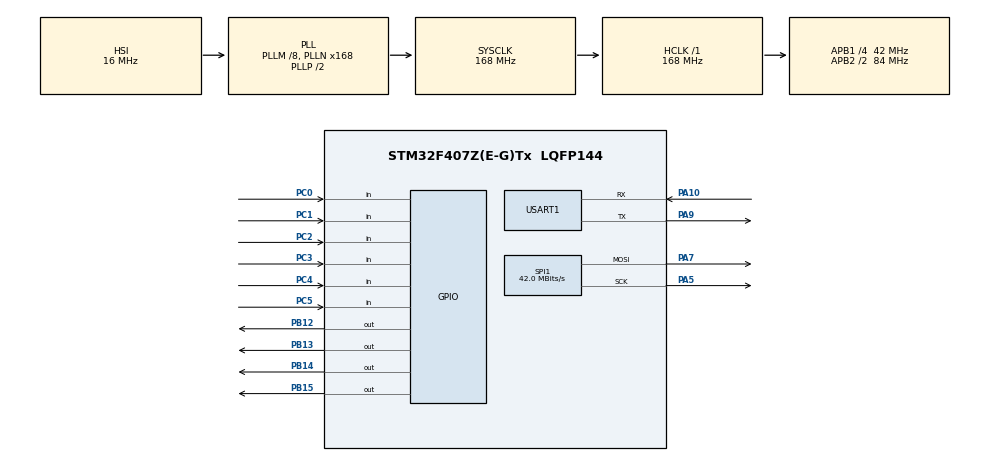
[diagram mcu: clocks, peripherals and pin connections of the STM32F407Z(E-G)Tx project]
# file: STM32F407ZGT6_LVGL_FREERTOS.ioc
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FREERTOS.Tasks01=defaultTask,24,128,StartDefaultTask,Default,NULL,Dynamic,NULL,NULL
Mcu.Family=STM32F4
Mcu.Name=STM32F407Z(E-G)Tx
Mcu.Package=LQFP144
NVIC.PriorityGroup=NVIC_PRIORITYGROUP_4
NVIC.TIM6_DAC_IRQn=true\:15\:0\:false\:false\:true\:false\:false\:true\:true
NVIC.TimeBase=TIM6_DAC_IRQn
NVIC.TimeBaseIP=TIM6
NVIC.USART1_IRQn=true\:5\:0\:false\:false\:true\:true\:true\:true\:true
PA10.Mode=Asynchronous
PA10.Signal=USART1_RX
PA5.Mode=TX_Only_Simplex_Unidirect_Master
PA5.Signal=SPI1_SCK
PA7.Mode=TX_Only_Simplex_Unidirect_Master
PA7.Signal=SPI1_MOSI
PA9.Mode=Asynchronous
PA9.Signal=USART1_TX
PB12.Signal=GPIO_Output
PB13.Signal=GPIO_Output
PB14.Signal=GPIO_Output
PB15.Signal=GPIO_Output
PC0.GPIO_PuPd=GPIO_PULLUP
PC0.Signal=GPIO_Input
PC1.GPIO_PuPd=GPIO_PULLUP
PC1.Signal=GPIO_Input
PC2.GPIO_PuPd=GPIO_PULLUP
PC2.Signal=GPIO_Input
PC3.GPIO_PuPd=GPIO_PULLUP
PC3.Signal=GPIO_Input
PC4.GPIO_PuPd=GPIO_PULLUP
PC4.Signal=GPIO_Input
PC5.GPIO_PuPd=GPIO_PULLUP
PC5.Signal=GPIO_Input
ProjectManager.HeapSize=0x200
ProjectManager.StackSize=0x400
ProjectManager.TargetToolchain=MDK-ARM V5.32
RCC.48MHZClocksFreq_Value=84000000
RCC.AHBFreq_Value=168000000
RCC.APB1CLKDivider=RCC_HCLK_DIV4
RCC.APB1Freq_Value=42000000
RCC.APB1TimFreq_Value=84000000
RCC.APB2CLKDivider=RCC_HCLK_DIV2
RCC.APB2Freq_Value=84000000
RCC.APB2TimFreq_Value=168000000
RCC.CortexFreq_Value=168000000
RCC.HCLKFreq_Value=168000000
RCC.HSE_VALUE=25000000
RCC.HSI_VALUE=16000000
RCC.LSE_VALUE=32768
RCC.PLLM=8
RCC.PLLN=168
RCC.SYSCLKFreq_VALUE=168000000
RCC.SYSCLKSource=RCC_SYSCLKSOURCE_PLLCLK
RCC.VCOOutputFreq_Value=336000000
SPI1.CalculateBaudRate=42.0 MBits/s
SPI1.Direction=SPI_DIRECTION_2LINES
SPI1.Mode=SPI_MODE_MASTER
SPI1.VirtualType=VM_MASTER
USART1.VirtualMode=VM_ASYNC
VP_FREERTOS_VS_CMSIS_V2.Mode=CMSIS_V2
VP_SYS_VS_tim6.Mode=TIM6
board=custom

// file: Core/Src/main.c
/* USER CODE BEGIN Header */
/**
  ******************************************************************************
  * @file           : main.c
  * @brief          : Main program body
  ******************************************************************************
  * @attention
  *
  * Copyright (c) 2026 STMicroelectronics.
  * All rights reserved.
  *
  * This software is licensed under terms that can be found in the LICENSE file
  * in the root directory of this software component.
  * If no LICENSE file comes with this software, it is provided AS-IS.
  *
  ******************************************************************************
  */
/* USER CODE END Header */
#include "main.h"
#include "cmsis_os.h"

/* USER CODE BEGIN Includes */
#include "lvgl.h"
#include "lv_port_disp.h"
#include "indev_port.h"
#include "app_framework.h"
/* ★吊毛加：真 RTOS 版多任务（HostTasks_Init / gui_task_body 声明在这里） */
#include "rtos_tasks_reference.h"
/* USER CODE END Includes */

SPI_HandleTypeDef hspi1;

UART_HandleTypeDef huart1;

/* Definitions for defaultTask */
osThreadId_t defaultTaskHandle;
const osThreadAttr_t defaultTask_attributes = {
  .name = "defaultTask",
  .stack_size = 128 * 4,
  .priority = (osPriority_t) osPriorityNormal,
};

void SystemClock_Config(void);
static void MX_GPIO_Init(void);
static void MX_SPI1_Init(void);
static void MX_USART1_UART_Init(void);
void StartDefaultTask(void *argument);

int main(void)
{

  /* MCU Configuration--------------------------------------------------------*/

  /* Reset of all peripherals, Initializes the Flash interface and the Systick. */
  HAL_Init();

  /* Configure the system clock */
  SystemClock_Config();

  /* Initialize all configured peripherals */
  MX_GPIO_Init();
  MX_SPI1_Init();
  MX_USART1_UART_Init();

  /* Init scheduler */
  osKernelInitialize();

  /* USER CODE BEGIN RTOS_MUTEX */
  /* ★吊毛加（唯�?�?要你手写的一行）：建内核对象 + 协议接线 + �? 4 个任�?
   *   HostTasks_Init() 内部依次做：
   *     1) osMutexNew      �? g_lvgl_mutex（开优先级继承）
   *     2) osMessageQueueNew 建发送队列（深度 8 × proto_tx_item_t�?
   *     3) ProtoF407_Init(&huart1)    —�?? 注册 TX hook + �? RXNE 中断
   *     4) ProtoF407_SetTxQueue(...)  —�?? �? PROTO_Send 投队列�?�非直发
   *     5) osThreadNew(gui/prx/ptx/input) —�?? 建任务（gui �? 4KB，不�? CubeMX�?
   *     6) ProtoF407_BindRxTask(...)  —�?? �? prx 句柄交给中断做�?�知唤醒
   *   必须�? osKernelInitialize 之后、osKernelStart 之前（调度器未起，任务只是挂进就绪表）�?? */
  HostTasks_Init();
  /* USER CODE END RTOS_MUTEX */

  /* Create the thread(s) */
  /* creation of defaultTask */
  defaultTaskHandle = osThreadNew(StartDefaultTask, NULL, &defaultTask_attributes);

  /* Start scheduler */
  osKernelStart();

  /* We should never get here as control is now taken by the scheduler */

  /* Infinite loop */
  while (1)
  {

  }
}

void SystemClock_Config(void)
{
  RCC_OscInitTypeDef RCC_OscInitStruct = {0};
  RCC_ClkInitTypeDef RCC_ClkInitStruct = {0};

  /** Configure the main internal regulator output voltage
  */
  __HAL_RCC_PWR_CLK_ENABLE();
  __HAL_PWR_VOLTAGESCALING_CONFIG(PWR_REGULATOR_VOLTAGE_SCALE1);

  /** Initializes the RCC Oscillators according to the specified parameters
  * in the RCC_OscInitTypeDef structure.
  */
  RCC_OscInitStruct.OscillatorType = RCC_OSCILLATORTYPE_HSI;
  RCC_OscInitStruct.HSIState = RCC_HSI_ON;
  RCC_OscInitStruct.HSICalibrationValue = RCC_HSICALIBRATION_DEFAULT;
  RCC_OscInitStruct.PLL.PLLState = RCC_PLL_ON;
  RCC_OscInitStruct.PLL.PLLSource = RCC_PLLSOURCE_HSI;
  RCC_OscInitStruct.PLL.PLLM = 8;
  RCC_OscInitStruct.PLL.PLLN = 168;
  RCC_OscInitStruct.PLL.PLLP = RCC_PLLP_DIV2;
  RCC_OscInitStruct.PLL.PLLQ = 4;
  if (HAL_RCC_OscConfig(&RCC_OscInitStruct) != HAL_OK)
  {
    Error_Handler();
  }

  /** Initializes the CPU, AHB and APB buses clocks
  */
  RCC_ClkInitStruct.ClockType = RCC_CLOCKTYPE_HCLK|RCC_CLOCKTYPE_SYSCLK
                              |RCC_CLOCKTYPE_PCLK1|RCC_CLOCKTYPE_PCLK2;
  RCC_ClkInitStruct.SYSCLKSource = RCC_SYSCLKSOURCE_PLLCLK;
  RCC_ClkInitStruct.AHBCLKDivider = RCC_SYSCLK_DIV1;
  RCC_ClkInitStruct.APB1CLKDivider = RCC_HCLK_DIV4;
  RCC_ClkInitStruct.APB2CLKDivider = RCC_HCLK_DIV2;

  if (HAL_RCC_ClockConfig(&RCC_ClkInitStruct, FLASH_LATENCY_5) != HAL_OK)
  {
    Error_Handler();
  }
}

static void MX_SPI1_Init(void)
{

  /* SPI1 parameter configuration*/
  hspi1.Instance = SPI1;
  hspi1.Init.Mode = SPI_MODE_MASTER;
  hspi1.Init.Direction = SPI_DIRECTION_2LINES;
  hspi1.Init.DataSize = SPI_DATASIZE_8BIT;
  hspi1.Init.CLKPolarity = SPI_POLARITY_LOW;
  hspi1.Init.CLKPhase = SPI_PHASE_1EDGE;
  hspi1.Init.NSS = SPI_NSS_SOFT;
  hspi1.Init.BaudRatePrescaler = SPI_BAUDRATEPRESCALER_2;
  hspi1.Init.FirstBit = SPI_FIRSTBIT_MSB;
  hspi1.Init.TIMode = SPI_TIMODE_DISABLE;
  hspi1.Init.CRCCalculation = SPI_CRCCALCULATION_DISABLE;
  hspi1.Init.CRCPolynomial = 10;
  if (HAL_SPI_Init(&hspi1) != HAL_OK)
  {
    Error_Handler();
  }

}

static void MX_USART1_UART_Init(void)
{

  huart1.Instance = USART1;
  huart1.Init.BaudRate = 115200;
  huart1.Init.WordLength = UART_WORDLENGTH_8B;
  huart1.Init.StopBits = UART_STOPBITS_1;
  huart1.Init.Parity = UART_PARITY_NONE;
  huart1.Init.Mode = UART_MODE_TX_RX;
  huart1.Init.HwFlowCtl = UART_HWCONTROL_NONE;
  huart1.Init.OverSampling = UART_OVERSAMPLING_16;
  if (HAL_UART_Init(&huart1) != HAL_OK)
  {
    Error_Handler();
  }

}

static void MX_GPIO_Init(void)
{
  GPIO_InitTypeDef GPIO_InitStruct = {0};

  /* GPIO Ports Clock Enable */
  __HAL_RCC_GPIOC_CLK_ENABLE();
  __HAL_RCC_GPIOA_CLK_ENABLE();
  __HAL_RCC_GPIOB_CLK_ENABLE();

  /*Configure GPIO pin Output Level */
  HAL_GPIO_WritePin(GPIOB, GPIO_PIN_12|GPIO_PIN_13|GPIO_PIN_14|GPIO_PIN_15, GPIO_PIN_RESET);

  /*Configure GPIO pins : PC0 PC1 PC2 PC3
                           PC4 PC5 */
  GPIO_InitStruct.Pin = GPIO_PIN_0|GPIO_PIN_1|GPIO_PIN_2|GPIO_PIN_3
                          |GPIO_PIN_4|GPIO_PIN_5;
  GPIO_InitStruct.Mode = GPIO_MODE_INPUT;
  GPIO_InitStruct.Pull = GPIO_PULLUP;
  HAL_GPIO_Init(GPIOC, &GPIO_InitStruct);

  /*Configure GPIO pins : PB12 PB13 PB14 PB15 */
  GPIO_InitStruct.Pin = GPIO_PIN_12|GPIO_PIN_13|GPIO_PIN_14|GPIO_PIN_15;
  GPIO_InitStruct.Mode = GPIO_MODE_OUTPUT_PP;
  GPIO_InitStruct.Pull = GPIO_NOPULL;
  GPIO_InitStruct.Speed = GPIO_SPEED_FREQ_LOW;
  HAL_GPIO_Init(GPIOB, &GPIO_InitStruct);

}

/* USER CODE BEGIN 4 */
/* ★ 吊毛加：FreeRTOS 护栏回调（配合 FreeRTOSConfig.h 的 STACK_OVERFLOW / MALLOC_FAILED 开关）。
 *   触发即在调试器停在这两函数里，看 pcTaskName / 调用栈即可定位是哪个任务溢出或堆耗尽。 */
void vApplicationStackOverflowHook(TaskHandle_t xTask, char *pcTaskName)
{
    (void)xTask;
    (void)pcTaskName;   /* 调试器里看 pcTaskName 即溢出任务名（如 "gui"） */
    __disable_irq();
    for (;;) { }        /* 在此下断点：栈溢出被 FreeRTOS 抓到，而非静默踩坏内核 */
}

void vApplicationMallocFailedHook(void)
{
    __disable_irq();
    for (;;) { }        /* 在此下断点：FreeRTOS 堆耗尽（pvPortMalloc 返回 NULL） */
}
/* USER CODE END 4 */

void StartDefaultTask(void *argument)
{
  /* USER CODE BEGIN 5 */
  /* ★吊毛改：gui 已由 HostTasks_Init() �? 4KB 栈另建（rtos_tasks_reference.c），
   *   不再复用本任�? —�?? 本任务栈�? CubeMX 生成�? 512B，跑 LVGL 必爆�?
   *   �?以这里直接把自己删掉，让位给真正�? gui 任务�?
   *   （原来那几行 lv_init/lv_port_disp_init/indev_port_init/app_framework_init
   *    已整体搬�? gui_task_body()，见 rtos_tasks_reference.c�? */
  (void)argument;
  /* ★ 改：不再自杀。osThreadTerminate(NULL) 会触发空闲任务的延迟 TCB 回收
   *   （prvCheckTasksWaitingTermination），一旦某任务栈溢出踩坏内核链表/全局量，
   *   空闲任务就在此死转、屏冻。本任务仅作占位，真活儿在 gui/prx/ptx/input。
   *   调通后整段删掉 StartDefaultTask（含 main.c 里的 osThreadNew）省 512B 栈。 */
  for(;;)
  {
    osDelay(1000);
  }
  /* USER CODE END 5 */
}

void HAL_TIM_PeriodElapsedCallback(TIM_HandleTypeDef *htim)
{
  if (htim->Instance == TIM6) {
    HAL_IncTick();
  }
}

void Error_Handler(void)
{
  __disable_irq();
  while (1)
  {
  }
}
